AUTOSAR XML (schema 4-0-3)
package /ComponentTypes
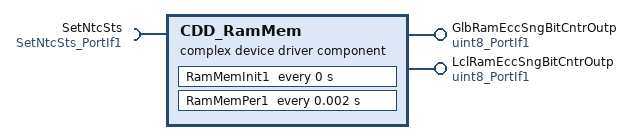
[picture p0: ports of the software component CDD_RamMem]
  complex device driver sw component type CDD_RamMem
    provide port GlbRamEccSngBitCntrOutp: nonqueued-sender-com-spec{data-element=Val, init-value=0}, provided-interface=uint8_PortIf1
    provide port LclRamEccSngBitCntrOutp: nonqueued-sender-com-spec{data-element=Val, init-value=0}, provided-interface=uint8_PortIf1
    require port SetNtcSts: client-com-spec=Oper, required-interface=SetNtcSts_PortIf1
    behavior CDD_RamMem_InternalBehavior
      ar-typed-per-instance-memorys:
        23 x data, all with sw-calibration-access=READ-ONLY:
          dRamMemCanRamDblBitEccErrAdr: type=uint32
          dRamMemCanRamSngBitEccErrAdr: type=uint32
          dRamMemDtsRamEccErrAdr: type=uint32
          dRamMemFrRamDblBitEccErrAdr: type=uint32
          dRamMemFrRamSngBitEccErrAdr: type=uint32
          dRamMemFrRamTmpBufADblBitEccErrAdr: type=uint32
          dRamMemFrRamTmpBufBDblBitEccErrAdr: type=uint32
          dRamMemGtmRamSngBitEccErrAdr: type=uint32
          dRamMemMCan0RamDblBitEccErrAdr: type=uint32
          dRamMemMCan1RamDblBitEccErrAdr: type=uint32
          dRamMemSpi{0..3}RamEccErrAdr: type=uint32
          dRamMemSpiRamEccErrAdr: type=uint32
          GlbRamEccSngBitCntr: type=uint8
          GlbRamEccSngBitSoftFailr: type=boolean
          GlbRamFailrAdr: type=uint32
          GlbRamWordLineRead: type=uint32
          LclRamEccSngBitCntr: type=uint8
          LclRamEccSngBitSoftFailr: type=boolean
          LclRamFailrAdr: type=uint32
          LclRamWordLineRead: type=uint32
      timing event CDD_RamMem_InitEvent: start-on-event=RamMemInit1, period=0
      timing event TMT_RamMemPer1: start-on-event=RamMemPer1, period=0.002
      runnable RamMemInit1
        sync call SC_SetNtcSts_Oper: operation=SetNtcSts.Oper, timeout=0
      runnable RamMemPer1
        data-send-points:
          access SEND_GlbRamEccSngBitCntrOutp_Val: accessed-variable=GlbRamEccSngBitCntrOutp.Val
          access SEND_LclRamEccSngBitCntrOutp_Val: accessed-variable=LclRamEccSngBitCntrOutp.Val
        sync call SC_SetNtcSts_Oper: operation=SetNtcSts.Oper, timeout=0
  swc implementation CDD_RamMem_Implementation: behavior=CDD_RamMem_InternalBehavior
    code-descriptors:
      code Default: artifact-descriptors=autosar-engineering-object={short-label=Default, category=SWSRC}
